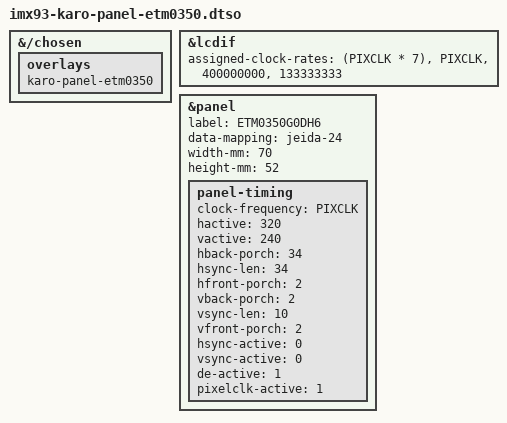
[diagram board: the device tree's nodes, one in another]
// SPDX-License-Identifier: (GPL-2.0 OR MIT)
/*
 * Copyright 2023 Lothar Waßmann <LW@KARO-electronics.de>
 *
 */

/dts-v1/;

/plugin/;

&{/chosen} {
	overlays {
		karo-panel-etm0350;
	};
};

#define PIXCLK 6520000

&lcdif {
	assigned-clock-rates = <(PIXCLK * 7)>, <PIXCLK>, <400000000>, <133333333>;
};

&panel {
	label = "ETM0350G0DH6";
	data-mapping = "jeida-24";
	width-mm = <70>;
	height-mm = <52>;
	status = "okay";

	panel-timing {
		clock-frequency = <PIXCLK>;
		hactive = <320>;
		vactive = <240>;
		hback-porch = <34>;
		hsync-len = <34>;
		hfront-porch = <2>;
		vback-porch = <2>;
		vsync-len = <10>;
		vfront-porch = <2>;
		hsync-active = <0>;
		vsync-active = <0>;
		de-active = <1>;
		pixelclk-active = <1>;
	};
};
